VERSION ""

NS_ :

BS_:

BU_:

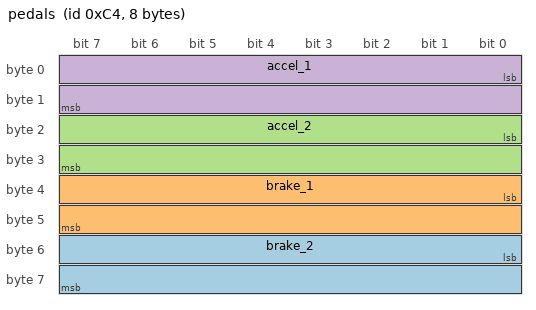
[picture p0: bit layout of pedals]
BO_ 196 pedals: 8 Vector__XXX
 SG_ brake_2 : 48|16@1+ (1,0) [0|0] "" Vector__XXX
 SG_ brake_1 : 32|16@1+ (1,0) [0|0] "" Vector__XXX
 SG_ accel_2 : 16|16@1+ (1,0) [0|0] "" Vector__XXX
 SG_ accel_1 : 0|16@1+ (1,0) [0|0] "" Vector__XXX
